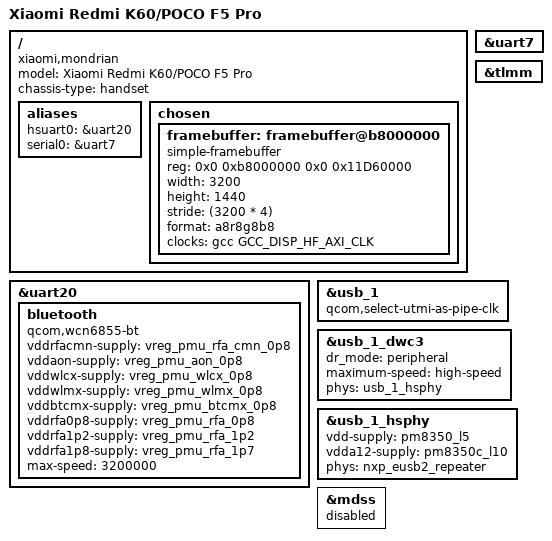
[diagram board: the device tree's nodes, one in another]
// SPDX-License-Identifier: BSD-3-Clause
/*
 * Copyright (c) 2026, AceEdg@
 * Based on SM8450 and SM8475 mainline support.
 *
 * Xiaomi Redmi K60 (mondrian) - Minimal Boot DTS
 */

#include <dt-bindings/arm/qcom,ids.h>
#include <dt-bindings/pinctrl/qcom,pmic-gpio.h>
#include <dt-bindings/regulator/qcom,rpmh-regulator.h>
#include <dt-bindings/leds/common.h>

#include "sm8475.dtsi"
#include "pm8350.dtsi"
#include "pm8350b.dtsi"
#include "pm8350c.dtsi"
#include "pm8450.dtsi"
#include "pmk8350.dtsi"
#include "pmr735a.dtsi"

/delete-node/ &adsp_mem;
/delete-node/ &rmtfs_mem;
/delete-node/ &xbl_ramdump_mem;
/delete-node/ &xbl_sc_mem;

/ {
	model = "Xiaomi Redmi K60/POCO F5 Pro";
	compatible = "xiaomi,mondrian", "qcom,sm8475", "qcom,sm8450";
	chassis-type = "handset";

	aliases {
		hsuart0 = &uart20;
		serial0 = &uart7;
	};
	
	chosen {
		#address-cells = <2>;
		#size-cells = <2>;
		ranges;
		
		//bootargs = "PMOS_NOSPLASH console=tty0";
		
		framebuffer: framebuffer@b8000000 {
			compatible = "simple-framebuffer";
			reg = <0x0 0xb8000000 0x0 0x11D60000>; // 12800 * 1440
			width = <3200>;
			height = <1440>;
			stride = <(3200 * 4)>;                 // 3200 * 4
			format = "a8r8g8b8";
			clocks = <&gcc GCC_DISP_HF_AXI_CLK>;
		};
	};
};

&uart7 {
	status = "okay";
};

&uart20 {
	status = "okay";

	bluetooth {
		compatible = "qcom,wcn6855-bt";

		vddrfacmn-supply = <&vreg_pmu_rfa_cmn_0p8>;
		vddaon-supply = <&vreg_pmu_aon_0p8>;
		vddwlcx-supply = <&vreg_pmu_wlcx_0p8>;
		vddwlmx-supply = <&vreg_pmu_wlmx_0p8>;
		vddbtcmx-supply = <&vreg_pmu_btcmx_0p8>;
		vddrfa0p8-supply = <&vreg_pmu_rfa_0p8>;
		vddrfa1p2-supply = <&vreg_pmu_rfa_1p2>;
		vddrfa1p8-supply = <&vreg_pmu_rfa_1p7>;

		max-speed = <3200000>;
	};
};

&tlmm {
	
};

/*
&ufs_mem_hc {
	status = "okay";
};

&ufs_mem_phy {
	status = "okay";
};
*/

&usb_1 {
	/* USB 2.0 only */
	qcom,select-utmi-as-pipe-clk;
	status = "okay";
};

&usb_1_dwc3 {
	dr_mode = "peripheral";
	maximum-speed = "high-speed";
	/* Remove USB3 phy */
	phys = <&usb_1_hsphy>;
	phy-names = "usb2-phy";
};

&usb_1_hsphy {
	vdd-supply = <&pm8350_l5>;
	vdda12-supply = <&pm8350c_l10>;

	phys = <&nxp_eusb2_repeater>;

	status = "okay";
};

&mdss {
	status = "disabled"; 
};
